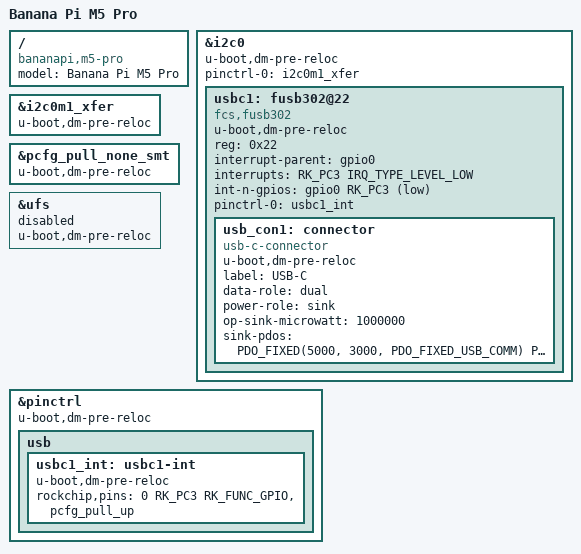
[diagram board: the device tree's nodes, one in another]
// SPDX-License-Identifier: (GPL-2.0+ OR MIT)
/*
 * Copyright (c) 2023 Rockchip Electronics Co., Ltd.
 */

/dts-v1/;
#include "rk3576.dtsi"
#include "rk3576-u-boot.dtsi"
#include <dt-bindings/input/input.h>
#include <dt-bindings/usb/pd.h>

/ {
	model = "Banana Pi M5 Pro";
	compatible = "bananapi,m5-pro", "rockchip,rk3576";
};

&i2c0 {
	u-boot,dm-pre-reloc;
	status = "okay";
	pinctrl-0 = <&i2c0m1_xfer>;
	usbc1: fusb302@22 {
		u-boot,dm-pre-reloc;
		compatible = "fcs,fusb302";
		reg = <0x22>;
		interrupt-parent = <&gpio0>;
		interrupts = <RK_PC3 IRQ_TYPE_LEVEL_LOW>;
		int-n-gpios = <&gpio0 RK_PC3 GPIO_ACTIVE_LOW>;
		pinctrl-names = "default";
		pinctrl-0 = <&usbc1_int>;
		status = "okay";
		usb_con1: connector {
			u-boot,dm-pre-reloc;
			compatible = "usb-c-connector";
			label = "USB-C";
			data-role = "dual";
			power-role = "sink";
			op-sink-microwatt = <1000000>;
			sink-pdos =
				<PDO_FIXED(5000, 3000, PDO_FIXED_USB_COMM)
				 PDO_VAR(5000, 12000, 5000)>;
		};
	};
};

&i2c0m1_xfer {
	u-boot,dm-pre-reloc;
};

&pcfg_pull_none_smt {
	u-boot,dm-pre-reloc;
};

&ufs {
	u-boot,dm-pre-reloc;
	status = "disabled";
};

&pinctrl {
	u-boot,dm-pre-reloc;
	usb {
		usbc1_int: usbc1-int {
			u-boot,dm-pre-reloc;
			rockchip,pins = <0 RK_PC3 RK_FUNC_GPIO &pcfg_pull_up>;
		};
	};
};
